# N32G401 register map
Vendor: Nationstech Ltd.; File version: 1.0
Registers are 32-bit, read-write, reset 0x0 unless marked. A register's access mark holds for its fields unless they carry their own. Offsets are from the block's base; [hi:lo] are bit positions; {n}, {i} and the like mark numbered series; 'fields as' and 'values as' point back to an identical list.

## PWR — Power control
Base 0x40007000
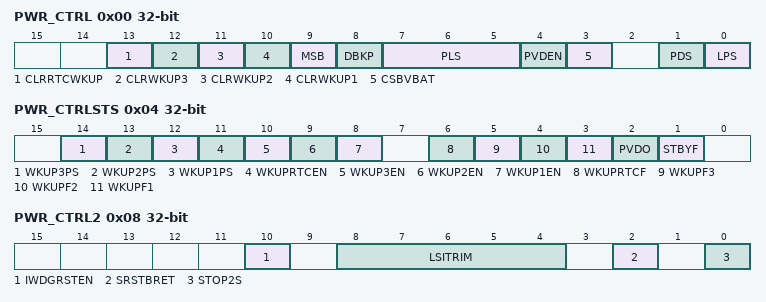
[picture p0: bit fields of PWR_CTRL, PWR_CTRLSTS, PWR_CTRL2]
0x00 PWR_CTRL
  [13] CLRRTCWKUP, [12] CLRWKUP3, [11] CLRWKUP2, [10] CLRWKUP1, [9] MSB, [8] DBKP, [7:5] PLS, [4] PVDEN, [3] CSBVBAT, [1] PDS, [0] LPS
0x04 PWR_CTRLSTS
  [14] WKUP3PS, [13] WKUP2PS, [12] WKUP1PS, [11] WKUPRTCEN, [10] WKUP3EN, [9] WKUP2EN, [8] WKUP1EN, [6] WKUPRTCF, [5] WKUPF3, [4] WKUPF2, [3] WKUPF1, [2] PVDO, [1] STBYF
0x08 PWR_CTRL2
  [10] IWDGRSTEN, [8:4] LSITRIM, [2] SRSTBRET, [0] STOP2S

## RCC — Reset and clock control
Base 0x40021000
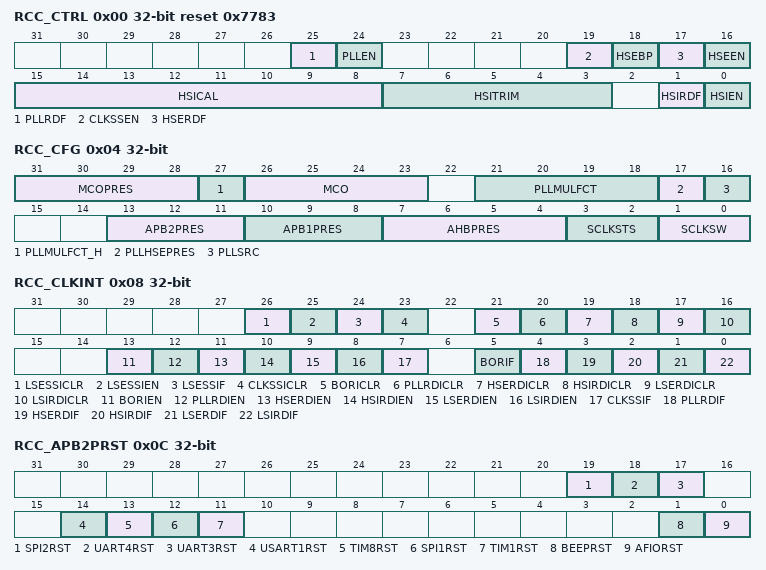
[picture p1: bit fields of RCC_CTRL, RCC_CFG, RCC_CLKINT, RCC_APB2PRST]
0x00 RCC_CTRL reset 0x7783
  [25] PLLRDF, [24] PLLEN, [19] CLKSSEN, [18] HSEBP, [17] HSERDF, [16] HSEEN, [15:8] HSICAL, [7:3] HSITRIM, [1] HSIRDF, [0] HSIEN
0x04 RCC_CFG
  [31:28] MCOPRES, [27] PLLMULFCT_H, [26:23] MCO, [21:18] PLLMULFCT, [17] PLLHSEPRES, [16] PLLSRC, [13:11] APB2PRES, [10:8] APB1PRES, [7:4] AHBPRES, [3:2] SCLKSTS, [1:0] SCLKSW
0x08 RCC_CLKINT
  [26] LSESSICLR, [25] LSESSIEN, [24] LSESSIF, [23] CLKSSICLR, [21] BORICLR, [20] PLLRDICLR, [19] HSERDICLR, [18] HSIRDICLR, [17] LSERDICLR, [16] LSIRDICLR, [13] BORIEN, [12] PLLRDIEN, [11] HSERDIEN, [10] HSIRDIEN, [9] LSERDIEN, [8] LSIRDIEN, [7] CLKSSIF, [5] BORIF, [4] PLLRDIF, [3] HSERDIF, [2] HSIRDIF, [1] LSERDIF, [0] LSIRDIF
0x0C RCC_APB2PRST
  [19] SPI2RST, [18] UART4RST, [17] UART3RST, [14] USART1RST, [13] TIM8RST, [12] SPI1RST, [11] TIM1RST, [1] BEEPRST, [0] AFIORST
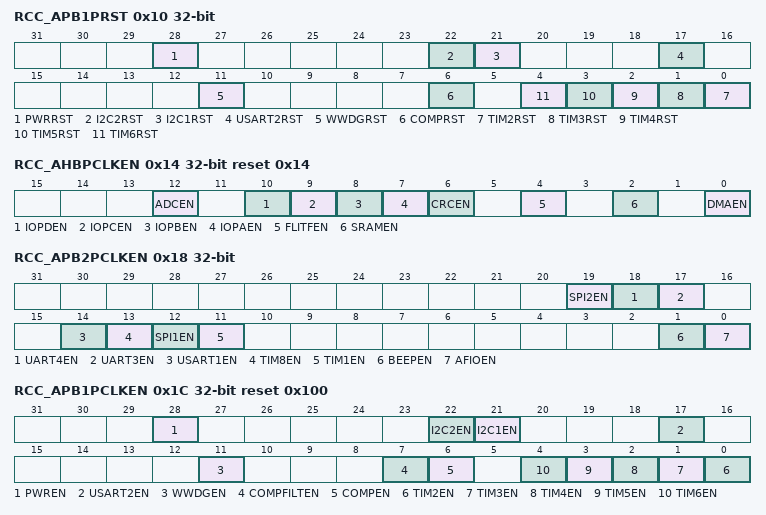
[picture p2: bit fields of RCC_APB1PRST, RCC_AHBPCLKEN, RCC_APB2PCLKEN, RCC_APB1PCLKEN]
0x10 RCC_APB1PRST
  [28] PWRRST, [22] I2C2RST, [21] I2C1RST, [17] USART2RST, [11] WWDGRST, [6] COMPRST, [n-2] TIM{n}RST (n=2..6)
0x14 RCC_AHBPCLKEN reset 0x14
  [12] ADCEN, [10] IOPDEN, [9] IOPCEN, [8] IOPBEN, [7] IOPAEN, [6] CRCEN, [4] FLITFEN, [2] SRAMEN, [0] DMAEN
0x18 RCC_APB2PCLKEN
  [19] SPI2EN, [18] UART4EN, [17] UART3EN, [14] USART1EN, [13] TIM8EN, [12] SPI1EN, [11] TIM1EN, [1] BEEPEN, [0] AFIOEN
0x1C RCC_APB1PCLKEN reset 0x100
  [28] PWREN, [22] I2C2EN, [21] I2C1EN, [17] USART2EN, [11] WWDGEN, [7] COMPFILTEN, [6] COMPEN, [n-2] TIM{n}EN (n=2..6)
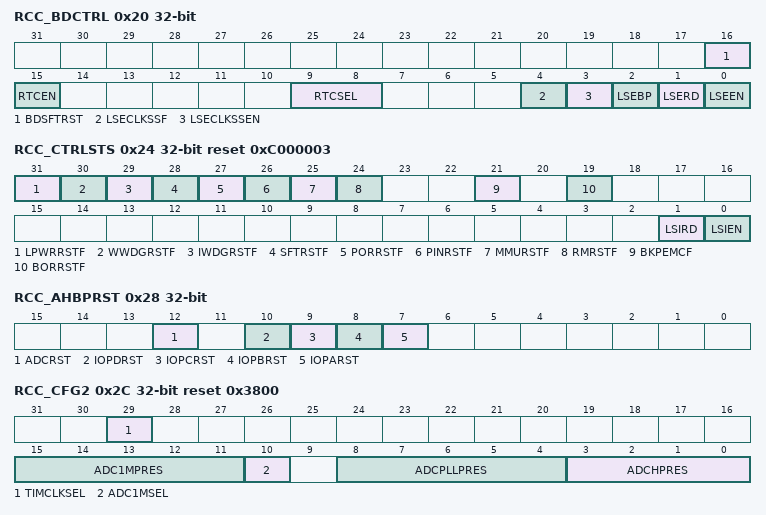
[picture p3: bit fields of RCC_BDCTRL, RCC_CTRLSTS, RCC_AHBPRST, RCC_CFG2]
0x20 RCC_BDCTRL
  [16] BDSFTRST, [15] RTCEN, [9:8] RTCSEL, [4] LSECLKSSF, [3] LSECLKSSEN, [2] LSEBP, [1] LSERD, [0] LSEEN
0x24 RCC_CTRLSTS reset 0xC000003
  [31] LPWRRSTF, [30] WWDGRSTF, [29] IWDGRSTF, [28] SFTRSTF, [27] PORRSTF, [26] PINRSTF, [25] MMURSTF, [24] RMRSTF, [21] BKPEMCF, [19] BORRSTF, [1] LSIRD, [0] LSIEN
0x28 RCC_AHBPRST
  [12] ADCRST, [10] IOPDRST, [9] IOPCRST, [8] IOPBRST, [7] IOPARST
0x2C RCC_CFG2 reset 0x3800
  [29] TIMCLKSEL, [15:11] ADC1MPRES, [10] ADC1MSEL, [8:4] ADCPLLPRES, [3:0] ADCHPRES
0x30 RCC_CFG3 reset 0x40
  [6] BORRSTEN
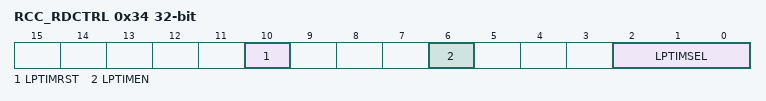
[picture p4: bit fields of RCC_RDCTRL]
0x34 RCC_RDCTRL
  [10] LPTIMRST, [6] LPTIMEN, [2:0] LPTIMSEL
0x40 RCC_PLLHSIPRE reset 0x1
  [0] PLLHSIPRE
0x80 RCC_AHB1CLKEN reset 0x1
  [0] ADCHCLKEN

## RTC — Real time clock
Base 0x40002800
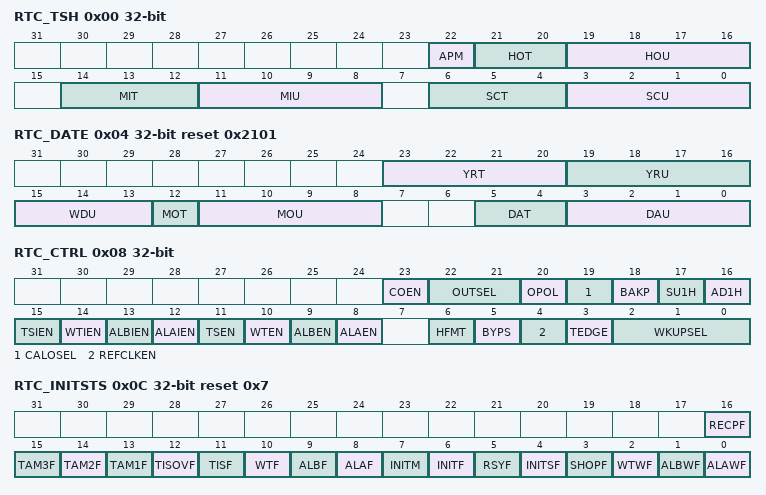
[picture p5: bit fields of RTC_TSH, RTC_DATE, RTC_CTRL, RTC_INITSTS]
0x00 RTC_TSH
  [22] APM, [21:20] HOT, [19:16] HOU, [14:12] MIT, [11:8] MIU, [6:4] SCT, [3:0] SCU
0x04 RTC_DATE reset 0x2101
  [23:20] YRT, [19:16] YRU, [15:13] WDU, [12] MOT, [11:8] MOU, [5:4] DAT, [3:0] DAU
0x08 RTC_CTRL
  [23] COEN, [22:21] OUTSEL, [20] OPOL, [19] CALOSEL, [18] BAKP, [17] SU1H, [16] AD1H, [15] TSIEN, [14] WTIEN, [13] ALBIEN, [12] ALAIEN, [11] TSEN, [10] WTEN, [9] ALBEN, [8] ALAEN, [6] HFMT, [5] BYPS, [4] REFCLKEN, [3] TEDGE, [2:0] WKUPSEL
0x0C RTC_INITSTS reset 0x7 (reset mask 0x17FFF)
  [16] RECPF, [15] TAM3F, [14] TAM2F, [13] TAM1F, [12] TISOVF, [11] TISF, [10] WTF, [9] ALBF, [8] ALAF, [7] INITM, [6] INITF, [5] RSYF, [4] INITSF, [3] SHOPF, [2] WTWF, [1] ALBWF, [0] ALAWF
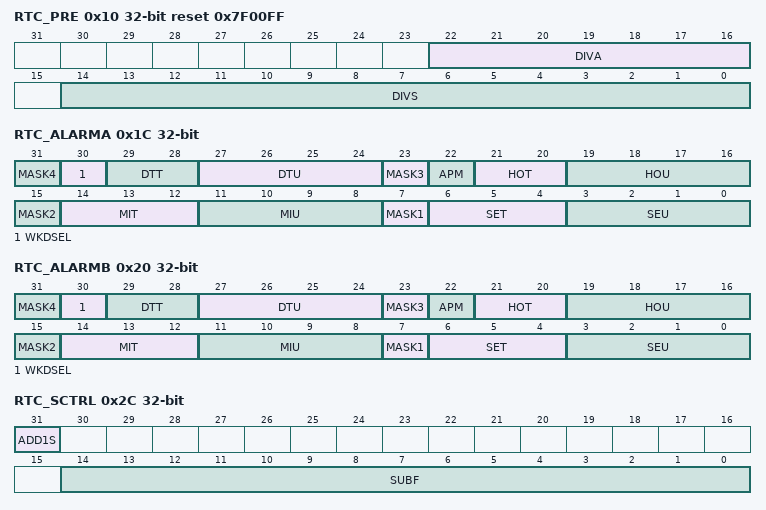
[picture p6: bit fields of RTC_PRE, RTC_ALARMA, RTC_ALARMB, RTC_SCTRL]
0x10 RTC_PRE reset 0x7F00FF
  [22:16] DIVA, [14:0] DIVS
0x14 RTC_WKUPT reset 0xFFFF
  [15:0] WKUPT
0x1C RTC_ALARMA
  [8n-1] MASK{n} (n=1..4), [30] WKDSEL, [29:28] DTT, [27:24] DTU, [22] APM, [21:20] HOT, [19:16] HOU, [14:12] MIT, [11:8] MIU, [6:4] SET, [3:0] SEU
0x20 RTC_ALARMB
  fields as RTC_ALARMA
0x24 RTC_WRP
  [7:0] PKEY
0x28 RTC_SUBS
  [15:0] SS
0x2C RTC_SCTRL
  [31] ADD1S, [14:0] SUBF
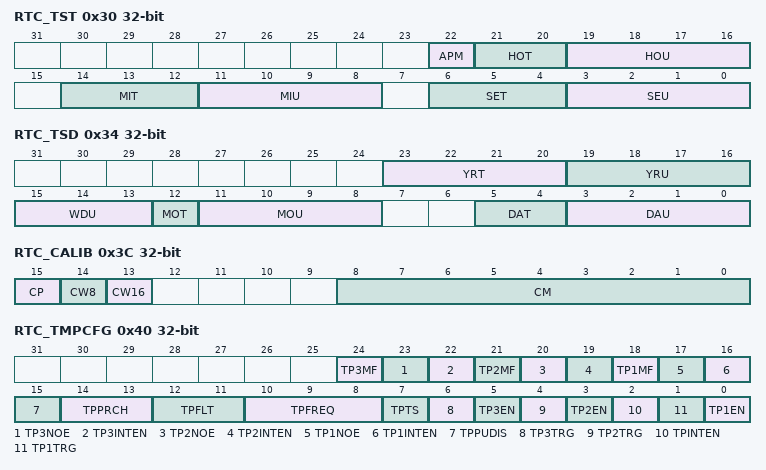
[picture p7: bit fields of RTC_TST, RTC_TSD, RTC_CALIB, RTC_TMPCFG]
0x30 RTC_TST (reset mask 0x7F)
  [22] APM, [21:20] HOT, [19:16] HOU, [14:12] MIT, [11:8] MIU, [6:4] SET, [3:0] SEU
0x34 RTC_TSD
  fields as RTC_DATE
0x38 RTC_TSSS
  [15:0] SSE
0x3C RTC_CALIB (reset mask 0xFF)
  [15] CP, [14] CW8, [13] CW16, [8:0] CM
0x40 RTC_TMPCFG (reset mask 0x2DFF9F)
  [24] TP3MF, [23] TP3NOE, [22] TP3INTEN, [21] TP2MF, [20] TP2NOE, [19] TP2INTEN, [18] TP1MF, [17] TP1NOE, [16] TP1INTEN, [15] TPPUDIS, [14:13] TPPRCH, [12:11] TPFLT, [10:8] TPFREQ, [7] TPTS, [6] TP3TRG, [5] TP3EN, [4] TP2TRG, [3] TP2EN, [2] TPINTEN, [1] TP1TRG, [0] TP1EN
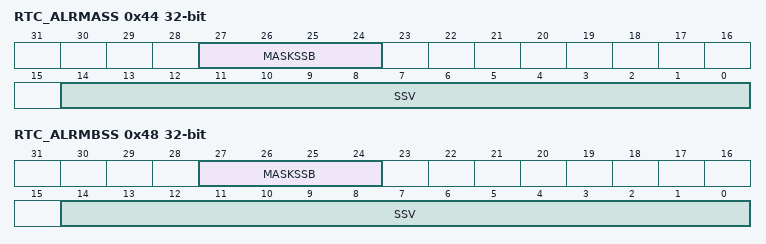
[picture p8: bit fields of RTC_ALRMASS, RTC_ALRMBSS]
0x44 RTC_ALRMASS
  [27:24] MASKSSB, [14:0] SSV
0x48 RTC_ALRMBSS
  [27:24] MASKSSB, [14:0] SSV
0x4C RTC_OPT
  [0] TYPE
{0x4C+4i} RTC_BKP{i} (i=1..20)
  [31:0] BF

## SPI1 — Serial peripheral interface
Base 0x40013000
Same registers: SPI2 0x40013C00
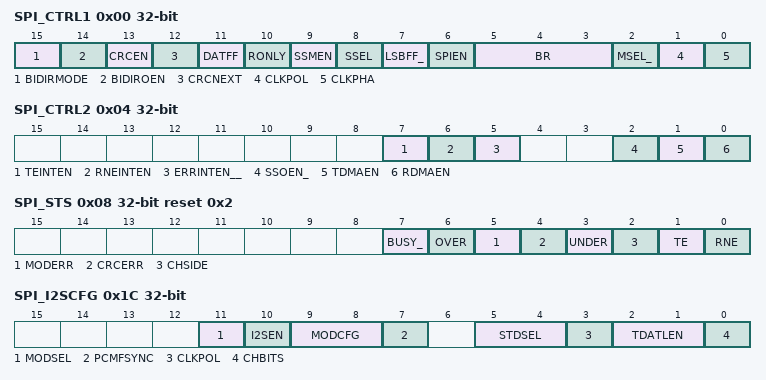
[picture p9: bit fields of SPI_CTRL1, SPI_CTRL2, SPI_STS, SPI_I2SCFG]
0x00 SPI_CTRL1
  [15] BIDIRMODE, [14] BIDIROEN, [13] CRCEN, [12] CRCNEXT, [11] DATFF, [10] RONLY, [9] SSMEN, [8] SSEL, [7] LSBFF_, [6] SPIEN, [5:3] BR, [2] MSEL_, [1] CLKPOL, [0] CLKPHA
0x04 SPI_CTRL2
  [7] TEINTEN, [6] RNEINTEN, [5] ERRINTEN__, [2] SSOEN_, [1] TDMAEN, [0] RDMAEN
0x08 SPI_STS reset 0x2
  [7] BUSY_, [6] OVER, [5] MODERR, [4] CRCERR, [3] UNDER, [2] CHSIDE, [1] TE, [0] RNE
0x0C SPI_DAT
  [15:0] DAT
0x10 SPI_CRCPOLY
  [15:0] CRCPOLY
0x14 SPI_CRCRDAT
  [15:0] CRCRDAT
0x18 SPI_CRCTDAT
  [15:0] CRCTDAT
0x1C SPI_I2SCFG
  [11] MODSEL, [10] I2SEN, [9:8] MODCFG, [7] PCMFSYNC, [5:4] STDSEL, [3] CLKPOL, [2:1] TDATLEN, [0] CHBITS
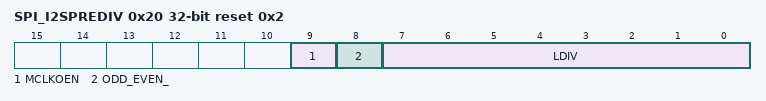
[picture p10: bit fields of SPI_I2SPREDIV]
0x20 SPI_I2SPREDIV reset 0x2
  [9] MCLKOEN, [8] ODD_EVEN_, [7:0] LDIV

## TIM6 — Basic timer
Base 0x40001000
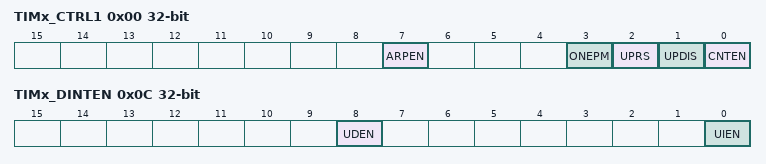
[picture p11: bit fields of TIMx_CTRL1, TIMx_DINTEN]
0x00 TIMx_CTRL1
  [7] ARPEN, [3] ONEPM, [2] UPRS, [1] UPDIS, [0] CNTEN
0x04 TIMx_CTRL2
  [6:4] MMSEL
0x0C TIMx_DINTEN
  [8] UDEN, [0] UIEN
0x10 TIMx_STS
  [0] UDITF
0x14 TIMx_EVTGEN
  [0] UDGN
0x24 TIMx_CNT 36-bit
  [15:0] CNT
0x28 TIMx_PSC
  [15:0] PSC
0x2C TIMx_AR
  [15:0] AR

## USART1 — Universal synchronous asynchronous receiver transmitter
Base 0x40013800
Same registers: USART2 0x40004400, UART3 0x40015000, UART4 0x40015400
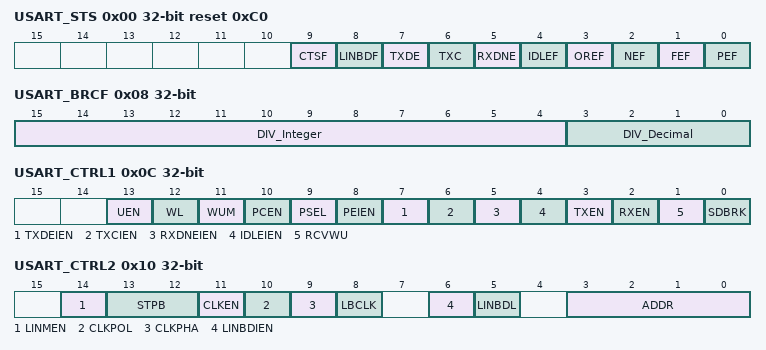
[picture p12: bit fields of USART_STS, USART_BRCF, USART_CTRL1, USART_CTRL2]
0x00 USART_STS reset 0xC0
  [9] CTSF, [8] LINBDF, [7] TXDE, [6] TXC, [5] RXDNE, [4] IDLEF, [3] OREF, [2] NEF, [1] FEF, [0] PEF
0x04 USART_DAT
  [8:0] DATV
0x08 USART_BRCF
  [15:4] DIV_Integer, [3:0] DIV_Decimal
0x0C USART_CTRL1
  [13] UEN, [12] WL, [11] WUM, [10] PCEN, [9] PSEL, [8] PEIEN, [7] TXDEIEN, [6] TXCIEN, [5] RXDNEIEN, [4] IDLEIEN, [3] TXEN, [2] RXEN, [1] RCVWU, [0] SDBRK
0x10 USART_CTRL2
  [14] LINMEN, [13:12] STPB, [11] CLKEN, [10] CLKPOL, [9] CLKPHA, [8] LBCLK, [6] LINBDIEN, [5] LINBDL, [3:0] ADDR
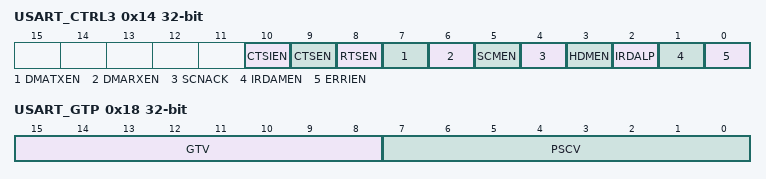
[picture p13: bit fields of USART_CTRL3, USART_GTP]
0x14 USART_CTRL3
  [10] CTSIEN, [9] CTSEN, [8] RTSEN, [7] DMATXEN, [6] DMARXEN, [5] SCMEN, [4] SCNACK, [3] HDMEN, [2] IRDALP, [1] IRDAMEN, [0] ERRIEN
0x18 USART_GTP
  [15:8] GTV, [7:0] PSCV

## WWDG — window watchdog
Base 0x40002C00
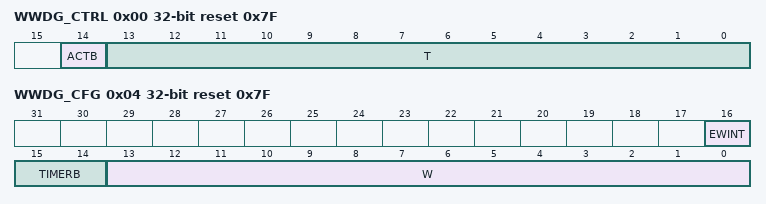
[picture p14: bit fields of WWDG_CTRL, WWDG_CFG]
0x00 WWDG_CTRL reset 0x7F (reset mask 0xFF)
  [14] ACTB, [13:0] T
0x04 WWDG_CFG reset 0x7F (reset mask 0x3FF)
  [16] EWINT, [15:14] TIMERB, [13:0] W
0x08 WWDG_STS
  [0] EWINTF
